AUTOSAR XML (schema 4-0-3)
standard types defined: UInt32, UInt8
package /AUTOSAR_Platform/DataConstrs
  range DC_UInt8: raw 0..255
package /PATAC/MSM/ComponentTypes
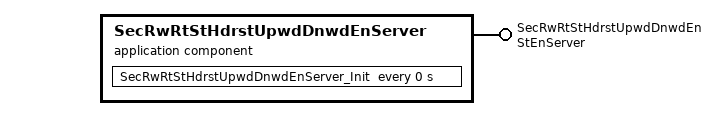
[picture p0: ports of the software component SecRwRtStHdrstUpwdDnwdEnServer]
  application sw component type SecRwRtStHdrstUpwdDnwdEnServer
    provide port SecRwRtStHdrstUpwdDnwdEn: provided-com-specs=[{operation=Clear, queue-length=1}, {operation=Get, queue-length=1}, {operation=Set, queue-length=1}], provided-interface=StEnServer
    behavior SecRwRtStHdrstUpwdDnwdEnServer_InternalBehavior
      operation invoked event OIT_SecRwRtStHdrstUpwdDnwdEn_Clear_SecRwRtStHdrstUpwdDnwdEn_Clear: start-on-event=SecRwRtStHdrstUpwdDnwdEn_Clear, operation=SecRwRtStHdrstUpwdDnwdEn.Clear
      operation invoked event OIT_SecRwRtStHdrstUpwdDnwdEn_Get_SecRwRtStHdrstUpwdDnwdEn_Get: start-on-event=SecRwRtStHdrstUpwdDnwdEn_Get, operation=SecRwRtStHdrstUpwdDnwdEn.Get
      operation invoked event OIT_SecRwRtStHdrstUpwdDnwdEn_Set_SecRwRtStHdrstUpwdDnwdEn_Set: start-on-event=SecRwRtStHdrstUpwdDnwdEn_Set, operation=SecRwRtStHdrstUpwdDnwdEn.Set
      timing event SecRwRtStHdrstUpwdDnwdEnServer_InitEvent: start-on-event=SecRwRtStHdrstUpwdDnwdEnServer_Init, period=0
      4 x runnable:
        SecRwRtStHdrstUpwdDnwdEn_Clear
        SecRwRtStHdrstUpwdDnwdEn_Get
        SecRwRtStHdrstUpwdDnwdEn_Set
        SecRwRtStHdrstUpwdDnwdEnServer_Init
  swc implementation SecRwRtStHdrstUpwdDnwdEnServer_Implementation: behavior=SecRwRtStHdrstUpwdDnwdEnServer_InternalBehavior
    code-descriptors:
      code Default: artifact-descriptors=autosar-engineering-object={short-label=Default, category=SWSRC}
package /PATAC/MSM/ModeAdjust/PortInterface
  client server interface StEnServer
    operation Clear
      arg data: type=UInt8, direction=IN, server-argument-impl-policy=USE-ARGUMENT-TYPE
    operation Get
      arg data: type=UInt32, direction=OUT, server-argument-impl-policy=USE-ARGUMENT-TYPE
    operation Set
      arg data: type=UInt8, direction=IN, server-argument-impl-policy=USE-ARGUMENT-TYPE
